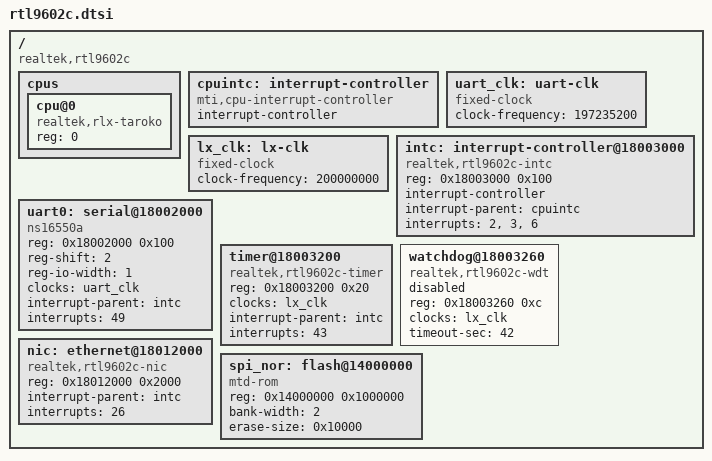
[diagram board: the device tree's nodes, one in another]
// SPDX-License-Identifier: GPL-2.0-or-later
/*
 * Realtek RTL9602C "Europa" GPON ONU SoC (RLX "Taroko" core).
 *
 * Clean-room device description derived from observed hardware facts
 * (register bases, IRQ numbers and clocks read from a running unit by
 * probing the live device).
 */

#include "luna.dtsi"

/ {
	#address-cells = <1>;
	#size-cells = <1>;
	compatible = "realtek,rtl9602c";

	cpus {
		#address-cells = <1>;
		#size-cells = <0>;

		cpu@0 {
			device_type = "cpu";
			compatible = "realtek,rlx-taroko";
			reg = <0>;
		};
	};

	cpuintc: interrupt-controller {
		#address-cells = <0>;
		#interrupt-cells = <1>;
		interrupt-controller;
		compatible = "mti,cpu-interrupt-controller";
	};

	/*
	 * SoC clocks (fixed): CPU 625 MHz, MEM 525 MHz, LX (bus) 200 MHz,
	 * SPI-F 50 MHz. The 16550 UART is fed from a 197.2352 MHz reference
	 * (base_baud 12327200 x 16).
	 */
	uart_clk: uart-clk {
		compatible = "fixed-clock";
		#clock-cells = <0>;
		clock-frequency = <197235200>;
	};

	/* LX (peripheral) bus clock, 200 MHz; feeds the SoC TC timer. */
	lx_clk: lx-clk {
		compatible = "fixed-clock";
		#clock-cells = <0>;
		clock-frequency = <200000000>;
	};

	intc: interrupt-controller@18003000 {
		compatible = "realtek,rtl9602c-intc";
		reg = <0x18003000 0x100>;
		interrupt-controller;
		#interrupt-cells = <1>;
		interrupt-parent = <&cpuintc>;
		/*
		 * The aggregator routes each input (GIRR nibble = target CP0 HW
		 * IRQ) onto one of several CP0 lines, not just line 2: the loaded
		 * routing uses values 2, 3 and 6 (e.g. the SoC timer is on 6).
		 * Cascade the dispatch on every CP0 line the routing targets so
		 * those interrupts are delivered (the dispatch scans all GISR
		 * words regardless of which line woke it).
		 */
		interrupts = <2>, <3>, <6>;
	};

	uart0: serial@18002000 {
		compatible = "ns16550a";
		reg = <0x18002000 0x100>;
		reg-shift = <2>;
		reg-io-width = <1>;
		clocks = <&uart_clk>;
		interrupt-parent = <&intc>;
		interrupts = <49>;
		status = "okay";
	};

	timer@18003200 {
		/*
		 * SoC "rlx timer" channel TC0 (CP0 Count is unreliable on this
		 * core, so this drives the system tick). The TC register block is
		 * at 0x18003200 (TC0 DATA/CNT/CTL/INT at +0x00/+0x04/+0x08/+0x0c);
		 * 0x18003100 is a different block whose +0x00 happens to be
		 * writable, which is why the earlier base accepted the reload
		 * write yet the control/interrupt writes never stuck.
		 */
		compatible = "realtek,rtl9602c-timer";
		reg = <0x18003200 0x20>;
		clocks = <&lx_clk>;
		interrupt-parent = <&intc>;
		interrupts = <43>;
	};

	watchdog@18003260 {
		/*
		 * The SoC watchdog, at the top of the same TC block (TC_BASE +
		 * 0x60): WDT_CNT at +0x00 (bit 31 = kick), WDT_INTR at +0x04,
		 * WDT_CTRL at +0x08 (bit 31 enable, [30:29] tick scale,
		 * [26:22] phase-1 timeout, [19:15] phase-2 timeout, [1:0]
		 * reset mode).  It does not overlap the timer window above,
		 * which ends at +0x1f.
		 *
		 * The block is family-wide, not chip-specific -- the vendor
		 * BSP declares it once for every Luna part -- hence the
		 * generic compatible the driver actually binds on, with the
		 * chip name in front so a future chip-specific quirk has
		 * somewhere to go.
		 *
		 * The counter is scaled from the LX bus clock, so the window
		 * the driver can express follows &lx_clk: at 200 MHz one tick
		 * is 1.342 s at the coarsest scale and the ceiling is 42 s.
		 * That rate is not a fresh assumption -- the same &lx_clk
		 * drives the SoC timer above, which is this kernel's system
		 * tick, so a wrong LX frequency would already show up as a
		 * board that cannot keep time.
		 *
		 * 30 s is a working default, not a measurement: it is well
		 * inside that ceiling, and it is what procd asks for anyway
		 * once it opens /dev/watchdog, feeding at half the window.
		 *
		 * NOTE the arch restart path in arch/mips/realtek-luna/setup.c
		 * drives these same registers through a fixed KSEG1 address.
		 * That is deliberate and predates this node; the driver maps
		 * the window non-exclusively so both can coexist.
		 *
		 * ★★★ DISABLED 2026-08-26, AND THE REASON IS MEASURED, NOT A
		 * PREFERENCE. With this node enabled the board resets at ~29 s
		 * on EVERY boot of our image. Proven by a single-variable A/B
		 * pair and then by three more boots: with
		 * `initcall_blacklist=luna_wdt_driver_init` on the kernel
		 * command line the board reaches `br-lan: port 1(eth0) entered
		 * forwarding state` at 29.16 s, GPON `O3 -> O4` at 15.4 s, and
		 * prints NOT ONE `PRELOADER` line in a 90 s window. Without it,
		 * every attempt died at ~29 s with no panic and no oops -- the
		 * signature of a full-chip reset.
		 *
		 * ★ THE BLOCK IS NOT AT FAULT AND STOCK USES IT. The vendor
		 * image arms this same watchdog (rc34 -> /proc/luna_watchdog)
		 * and feeds it from a dedicated 5 s KERNEL thread. What we
		 * lack is that feeder: on our image the ONLY feeder is procd's
		 * single-threaded uloop, and the kernel core contributes zero
		 * pings once userspace opens the device, because we never set
		 * `max_hw_heartbeat_ms`. A multi-source audit could not close
		 * whether our kick RELOADS the counter at all.
		 *
		 * ★★ A WATCHDOG THAT BITES A HEALTHY BOARD IS NOT A RECOVERY
		 * MECHANISM, IT IS A FAULT -- so this is not "shipping less
		 * than stock", it is refusing to ship a reset every 29 s. The
		 * sibling RTL9603CVD node is disabled for the same class of
		 * reason.
		 *
		 * ⚠ OWED, and it is what re-enables this: prove the kick
		 * reloads (the audit's open question), or declare
		 * `max_hw_heartbeat_ms` so the kernel core keeps feeding
		 * between procd's pings. Until one of those is MEASURED, an
		 * enabled node costs this board every campaign.
		 */
		compatible = "realtek,rtl9602c-wdt", "realtek,rtl960x-wdt";
		reg = <0x18003260 0xc>;
		clocks = <&lx_clk>;
		/*
		 * ★★★ 42 s, THE HARDWARE MAXIMUM, AND IT IS A MEASUREMENT
		 * (2026-08-27).  At 30 s this board died at 29.2 s of EVERY
		 * boot -- half a second AFTER it was fully up:
		 *
		 *   [ 2.308] Luna WDT ... 30 s timeout (max 42 s)
		 *   [ 8.248] procd: - watchdog -        <- procd owns it now
		 *   [22.324] rtl9602c-gpon: PLM_TX ...
		 *            ... 6.8 s with NOTHING logged ...
		 *   [29.084] rtl9602c-gpon: full_sdk_datapath_init done
		 *   [29.176] br-lan: port 1(eth0) entered forwarding state
		 *   <reset -> PRELOADER -> NAND -> the vendor image>
		 *
		 * ⚠ THIS IS THE MARGIN, NOT THE FIX.  The real defect is the
		 * 6.8 s stall inside full_sdk_datapath_init: for that long
		 * nothing feeds the counter, which is precisely the stall a
		 * watchdog exists to catch.  Widening the window buys the boot
		 * and must not be read as the stall being acceptable -- it is
		 * recorded as owed work in the board file.
		 *
		 * ⚠ AND IT WAS DIAGNOSED BLIND FOR DAYS: without `loglevel=8`
		 * this kernel prints NOTHING (the inherited U-Boot `bootargs`
		 * is EMPTY on this board -- `printenv bootargs` proves it --
		 * so the console comes only from the DT `stdout-path` and the
		 * default loglevel hides every driver message).  Every earlier
		 * conclusion about this reset was reached without a kernel log.
		 */
		timeout-sec = <42>;

		/*
		 * ★★★ DISABLED AGAIN 2026-08-27, AFTER MEASURING WHAT THE
		 * RE-ENABLE EXISTED TO MEASURE. The re-enable's own premise was
		 * WRONG and is retracted here rather than quietly deleted:
		 *
		 *   ✗ "U-Boot hands this counter over ARMED, so a disabled node
		 *      does not remove the watchdog" -- REFUTED. A probe-time read
		 *      of WDT_CTRL before this driver touches anything:
		 *        DIAG phys=0x18003260 ctrl_on_entry=0x00000000
		 *      U-Boot leaves it OFF. The node being disabled really does
		 *      leave no watchdog, and the ~29 s reset was OURS all along.
		 *
		 * ★★ WHAT IS NOW PROVEN, so nobody re-chases any of it:
		 *   - the block IS at 0x18003260 on THIS chip: read live on the
		 *     board's own stock via /proc/rtl8686gmac/mem with both
		 *     neighbouring timers TICKING between two reads, and the
		 *     vendor's Luna BSP defines it as TC_BASE + 0x60. Two
		 *     independent tiers.
		 *   - STOCK arms it and stays up for hours: WDT_CTRL reads
		 *     0xe7c00000 (EN=1, scale 3, phase-1 = 31 = 41.6 s, phase-2 =
		 *     0), fed by a kernel thread `luna_watchdog` -- there is NO
		 *     /dev/watchdog on the vendor image at all.
		 *   - OUR writes LAND, byte for byte: with the window pinned so
		 *     procd cannot lower it, 39 arms all read back exactly what
		 *     they wrote (wrote=0xe7c00000 readback=0xe7c00000).
		 *   - AND THE WINDOW FOLLOWS phase-1 EXACTLY: phase-1 = 22 kills
		 *     the board at 30.1 s, phase-1 = 31 at ~42.2 s. The gap is
		 *     12.1 s = 9 ticks x 1.342 s, to the tenth. So it is this
		 *     counter, and it is measured from a FIXED origin (~0.6 s,
		 *     the chip coming out of reset) -- not from our enable.
		 *
		 * ★★★ THE ONE THING THAT DOES NOT WORK IS THE FEED, and it was
		 * attacked from every side available:
		 *   - the documented kick (write BIT(31) to WDT_CNT) -- kicks
		 *     land at 4.7/9.3/15.0/20.0/25.0/30.0 s and the reset still
		 *     arrives on the original schedule. Proven by TIMING, not by
		 *     read-back: WDT_CNT reads 0x00000000 on STOCK too, so it is
		 *     write-only and a read-back there proves nothing either way.
		 *   - rewriting WDT_CTRL on every ping -- ~16 rewrites in 25 s,
		 *     no effect on the deadline.
		 *   - toggling the enable (stop then start) -- no effect.
		 *   - the kick through the VENDOR'S OWN route, a literal KSEG1
		 *     store to 0xB8003260 instead of our ioremap -- no effect,
		 *     which exonerates the mapping and the accessor.
		 * With phase-1 at its ceiling our CTRL word is 0xe7c00000, which
		 * is BIT-IDENTICAL to what stock runs. Same register, same value,
		 * same physical address for the kick -- and stock lives while we
		 * die. The remaining difference is therefore NOT in this block's
		 * programming, and the next session should look for what else the
		 * vendor's platform code brings up around it, not at these bits.
		 *
		 * ★★ SO THIS IS NOT "SHIPPING LESS THAN STOCK", IT IS REFUSING TO
		 * SHIP A RESET EVERY 30-42 s. The ceiling is 41.6 s and the
		 * counter never restarts, so an ENABLED node reboots this board
		 * on a fixed timer whatever the software does -- it costs every
		 * campaign and measures nothing. The capability is OWED and is
		 * disclosed as a real difference against stock, never omitted.
		 */
		status = "disabled";
	};

	nic: ethernet@18012000 {
		/* re8686-class GMAC0; base confirmed on silicon (IDR0-5 hold the
		 * U-Boot MAC). INTC input 26 = GMAC0 TX/RX completion (matches live
		 * stock GIMR0/GISR0 bit26 and /proc/interrupts "26: ... eth0"). The
		 * driver request_irq()s this for IRQ-driven NAPI TX/RX servicing. */
		compatible = "realtek,rtl9602c-nic";
		reg = <0x18012000 0x2000>;
		interrupt-parent = <&intc>;
		interrupts = <26>;
		status = "okay";
	};

	spi_nor: flash@14000000 {
		/*
		 * 16 MB SPI-NOR, memory-mapped (physmap) at 0x14000000.
		 *
		 * READ-ONLY: this describes the controller's memory-map read
		 * window only, so map_rom binds and the MTD carries
		 * MTD_CAP_ROM. Program and erase live behind a separate
		 * register interface (SoC "SPI-F Gen3" PIO block) for which no
		 * driver exists yet -- until one does, nothing on this device
		 * can be written and the board keeps no setting across a
		 * reboot.
		 */
		compatible = "mtd-rom";
		reg = <0x14000000 0x1000000>;
		bank-width = <2>;
		/*
		 * The erase block, and it is LOAD-BEARING even on a read-only
		 * mapping. drivers/mtd/chips/map_rom.c default_erasesize()
		 * reads this property and, ABSENT IT, falls back to map->size
		 * -- the whole 16 MB chip as ONE erase block. The squashfs
		 * rootfs splitter rounds up to that block against the WHOLE
		 * DEVICE (mtdsplit_squashfs.c: mtd_roundup_to_eb(part_offset +
		 * squashfs_len, parent_mtd)), so a 3.2 MB rootfs rounded to
		 * 16 MB lands past the end of every partition and mtdpart.c
		 * publishes the overlay as
		 *     mtd: partition "rootfs_data" is out of reach -- disabled
		 * with size 0. Measured on the X111W 2026-08-16: /proc/mtd
		 * showed `rootfs_data` at size 0 with erasesize 0x01000000 --
		 * the chip -- which is exactly what that code path prints.
		 *
		 * 64 KiB is the JEDEC NOR sector and is a CONSERVATIVE choice:
		 * it is a valid alignment whatever the fitted part uses (a
		 * 4 KiB-sub-sector chip is aligned by it too), and with it the
		 * split yields a 1600 KiB rootfs_data inside the 4864 KiB
		 * bank-0 rootfs partition. It is a declaration, not a
		 * measurement -- this unit's flash has never been identified;
		 * confirm with a JEDEC RDID (0x9F) once the PIO path exists,
		 * at which point the chip reports its own block and this
		 * property is superseded.
		 */
		erase-size = <0x10000>;
		#address-cells = <1>;
		#size-cells = <1>;
	};
};
